# WS53 register map
File version: 0.1.0-experimental
Registers are 32-bit, read-write, no defined reset value unless marked. A register's access mark holds for its fields unless they carry their own. Offsets are from the block's base; [hi:lo] are bit positions; 'fields as' and 'values as' point back to an identical list.

## M_CRG
Base 0x52000000
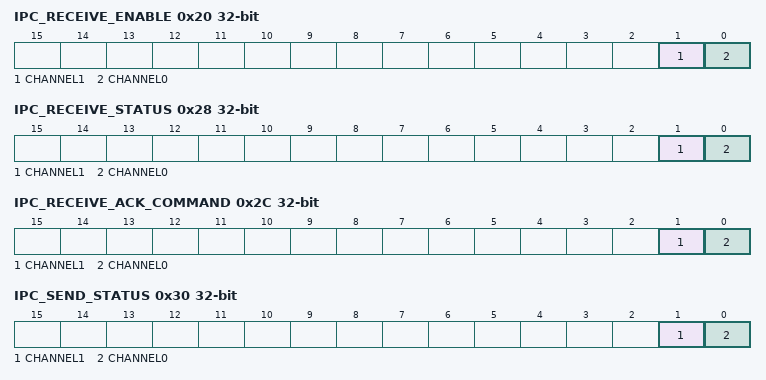
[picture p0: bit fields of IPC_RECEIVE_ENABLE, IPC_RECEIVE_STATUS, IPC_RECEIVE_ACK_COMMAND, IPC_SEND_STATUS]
0x20 IPC_RECEIVE_ENABLE wo
  [1] CHANNEL1, [0] CHANNEL0
0x28 IPC_RECEIVE_STATUS ro
  [1] CHANNEL1, [0] CHANNEL0
0x2C IPC_RECEIVE_ACK_COMMAND wo
  [1] CHANNEL1, [0] CHANNEL0
0x2C IPC_RECEIVE_ACK_SYNC ro (alternate view of IPC_RECEIVE_ACK_COMMAND)
  [31:0] UNSPECIFIED — Discard-only synchronization readback; value unspecified
0x30 IPC_SEND_STATUS ro
  [1] CHANNEL1, [0] CHANNEL0
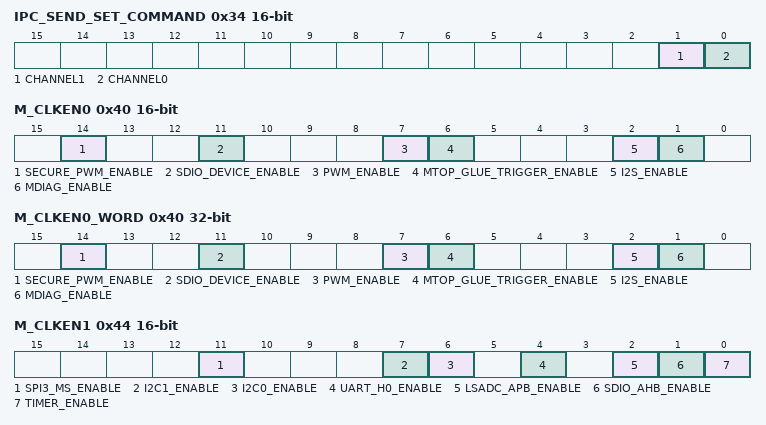
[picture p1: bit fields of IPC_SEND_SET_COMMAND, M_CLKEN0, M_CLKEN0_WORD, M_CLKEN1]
0x34 IPC_SEND_SET_COMMAND 16-bit wo
  [1] CHANNEL1, [0] CHANNEL0
0x38 IPC_RELEASE_COMMAND wo
  [31:0] RELEASE range 1..1
0x40 M_CLKEN0 16-bit
  [14] SECURE_PWM_ENABLE, [11] SDIO_DEVICE_ENABLE, [7] PWM_ENABLE, [6] MTOP_GLUE_TRIGGER_ENABLE, [2] I2S_ENABLE, [1] MDIAG_ENABLE
0x40 M_CLKEN0_WORD (alternate view of M_CLKEN0) — 32-bit little-endian access view of M_CLKEN0; same low-half fields, upper bits unmodeled; preserve them on RMW. SDK 163d9150: pwm_porting uses halfword access; sio_porting_clock_enable uses uapi_reg_setbit/clrbit with 32-bit unsigned int at the same address; upper bits unmodeled
  fields as M_CLKEN0
0x44 M_CLKEN1 16-bit
  [11] SPI3_MS_ENABLE — SPI3_MS = SDK application SPI_BUS_0
  [7] I2C1_ENABLE
  [6] I2C0_ENABLE
  [4] UART_H0_ENABLE — UART H0 = application UART1
  [2] LSADC_APB_ENABLE
  [1] SDIO_AHB_ENABLE
  [0] TIMER_ENABLE
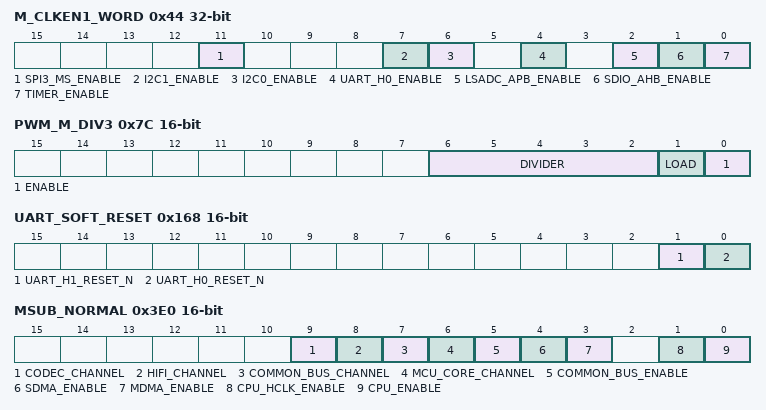
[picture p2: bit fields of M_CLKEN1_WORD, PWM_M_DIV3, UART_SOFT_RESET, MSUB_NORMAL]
0x44 M_CLKEN1_WORD (alternate view of M_CLKEN1) — 32-bit little-endian access view of M_CLKEN1; same low-half fields, upper bits unmodeled; preserve them on RMW. SDK 163d9150 libplat_patch.a:sdio_patch.c.obj:sdio_clock_set uses word loads/stores at M_CLKEN0/1, changing only SDIO bits11/1. Other peripheral ports retain halfword accesses; upper bits and reset values unknown. See evidence/ws53-sdio-clock-contract.json
  fields as M_CLKEN1
0x54 SOFT_RESET1
  [13] LSADC_RESET_N — ADC port uses 32-bit reg_clrbit/reg_setbit: assert low, delay 1us, release high, delay 1us
0x7C PWM_M_DIV3 16-bit
  [6:2] DIVIDER — SDK programs 16 but reports 32MHz. A-board bounded RAM experiment measured effective counter 32MHz/divider for values 1,2,4,8,16; upstream source identity and other values remain unverified. See evidence/ws53-pwm-divider-hil.json
  [1] LOAD — SDK explicitly clears then sets; no autonomous clearing inferred
  [0] ENABLE
0x168 UART_SOFT_RESET 16-bit
  [1] UART_H1_RESET_N — UART H1/application UART0 reset, active low; shared register, preserve other bits
  [0] UART_H0_RESET_N — UART H0/application UART1 reset, active low; shared register, preserve other bits
0x3E0 MSUB_NORMAL 16-bit
  [9] CODEC_CHANNEL
  [8] HIFI_CHANNEL
  [7] COMMON_BUS_CHANNEL
  [6] MCU_CORE_CHANNEL
  [5] COMMON_BUS_ENABLE
  [4] SDMA_ENABLE — Header-defined gate; does not prove SDMA instance accessibility
  [3] MDMA_ENABLE
  [1] CPU_HCLK_ENABLE
  [0] CPU_ENABLE
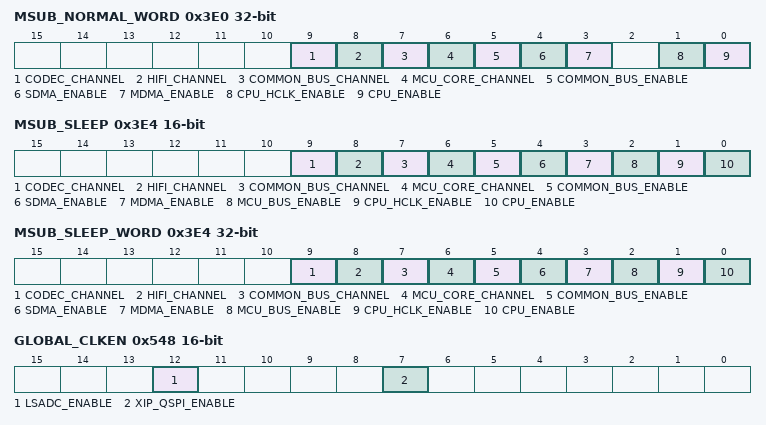
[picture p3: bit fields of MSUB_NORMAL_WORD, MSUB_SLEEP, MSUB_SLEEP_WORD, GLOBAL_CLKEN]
0x3E0 MSUB_NORMAL_WORD (alternate view of MSUB_NORMAL) — 32-bit little-endian access view of MSUB_NORMAL; same low-half fields, upper bits unmodeled; preserve them on RMW. SDK 163d9150: clock_recover.c/acore_clock_recover.c use reg_setbit/reg_clrbit, whose chip_io.h reg() is volatile uint32_t; original halfword write qualification remains unresolved. Historical 16/32-bit SDMA gate attempts both failed readback; this view proves neither gate clearing nor bus drain. See evidence/ws53-msub-word-access.json
  fields as MSUB_NORMAL
0x3E4 MSUB_SLEEP 16-bit
  [9] CODEC_CHANNEL, [8] HIFI_CHANNEL, [7] COMMON_BUS_CHANNEL, [6] MCU_CORE_CHANNEL, [5] COMMON_BUS_ENABLE, [4] SDMA_ENABLE, [3] MDMA_ENABLE, [2] MCU_BUS_ENABLE, [1] CPU_HCLK_ENABLE, [0] CPU_ENABLE
0x3E4 MSUB_SLEEP_WORD (alternate view of MSUB_SLEEP) — 32-bit little-endian access view of MSUB_SLEEP; same low-half fields, upper bits unmodeled; preserve them on RMW. SDK 163d9150: clock_recover.c/acore_clock_recover.c use 32-bit reg_setbit/reg_clrbit; pm_sleep_porting.c also uses reg32_setbit. chip_io.h defines volatile uint32_t accesses. Original halfword write qualification remains unresolved; both historical SDMA gate widths failed. This is not a bus-drain protocol. See evidence/ws53-msub-word-access.json
  fields as MSUB_SLEEP
0x548 GLOBAL_CLKEN 16-bit
  [12] LSADC_ENABLE — ADC port GLB_CLKEN_LSADC_OFFSET
  [7] XIP_QSPI_ENABLE — SPI_BUS_1 port enables the XIP QSPI global path; shared with XIP users
0x55C SPI_CLOCK 16-bit
  [0] ENABLE — SPI_BUS_0 port writes 1 to enable, 0 to disable; other fields unmodeled
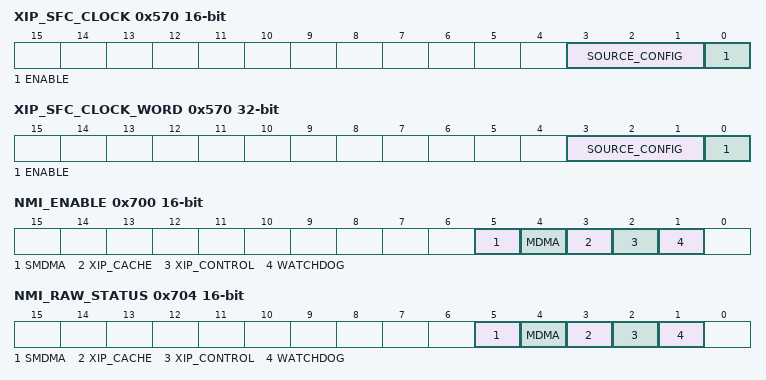
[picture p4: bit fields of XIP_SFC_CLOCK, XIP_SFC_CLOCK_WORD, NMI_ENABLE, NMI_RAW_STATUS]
0x570 XIP_SFC_CLOCK 16-bit
  [3:1] SOURCE_CONFIG — Three-bit configuration: sfc_switch_clock(pll=true) writes 6, pll=false writes 0; FlashBoot writes 6. Other encodings and any selector/divider decomposition or frequency are unqualified; this raw field is not a safe clock configuration API
  [0] ENABLE — SDK clears this bit before changing SOURCE_CONFIG, then sets it and optionally reads the word back. Source-level clock-enable usage only; setting it does not prove upstream clock presence or SFC readiness/drain
0x570 XIP_SFC_CLOCK_WORD (alternate view of XIP_SFC_CLOCK) — 32-bit little-endian access view of XIP_SFC_CLOCK; same low-half fields, upper bits unmodeled; preserve them on RMW. SDK-source 163d9150 clock_recover.c:sfc_switch_clock and flashboot_ws53/startup/main.c:boot_flash_clk_init at 0x52000570; chip_io.h word reg_setbit/reg_clrbit/readl plus halfword reg16_setbits/reg16_clrbits. Both views are the same shared clock resource; no reset, upper-bit semantics, complete frequency formula, safe live switching or ownership proven. See evidence/ws53-sfc-clock-source-contract.json
  fields as XIP_SFC_CLOCK
0x574 XIP_QSPI_CLOCK 16-bit
  [8:0] CONTROL
0x700 NMI_ENABLE 16-bit
  [5] SMDMA, [4] MDMA, [3] XIP_CACHE, [2] XIP_CONTROL, [1] WATCHDOG
0x704 NMI_RAW_STATUS 16-bit ro
  [5] SMDMA, [4] MDMA, [3] XIP_CACHE, [2] XIP_CONTROL, [1] WATCHDOG
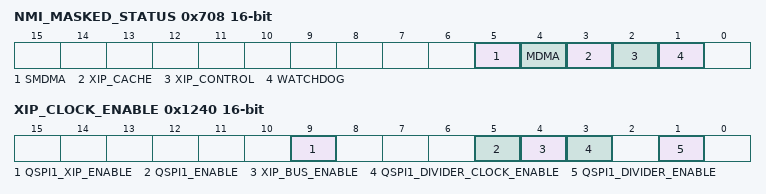
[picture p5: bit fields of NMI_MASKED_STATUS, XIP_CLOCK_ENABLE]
0x708 NMI_MASKED_STATUS 16-bit ro
  [5] SMDMA, [4] MDMA, [3] XIP_CACHE, [2] XIP_CONTROL, [1] WATCHDOG
0x950 SPI_DEVICE_MODE 16-bit
  [0] MASTER — SPI_BUS_0: 0 slave, 1 master; QSPI bus1 is master-only
0x1240 XIP_CLOCK_ENABLE 16-bit
  [9] QSPI1_XIP_ENABLE, [5] QSPI1_ENABLE, [4] XIP_BUS_ENABLE, [3] QSPI1_DIVIDER_CLOCK_ENABLE, [1] QSPI1_DIVIDER_ENABLE
0x1600 TRNG_RING_CONTROL 16-bit — TRNG_SEC_CFB: volatile shared ring control; SDK waits 200 us after enabling
  [0] RING_ENABLE
